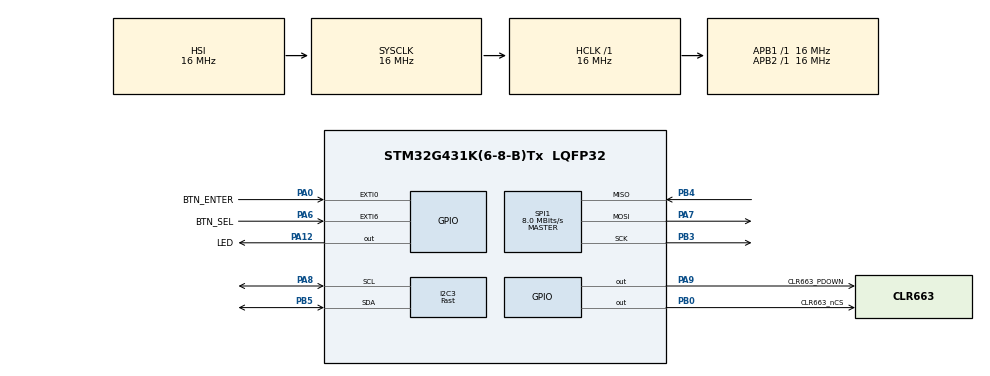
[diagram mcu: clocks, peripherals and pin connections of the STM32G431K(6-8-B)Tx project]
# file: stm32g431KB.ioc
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I2C3.I2C_Speed_Mode=I2C_Fast
I2C3.Timing=0x0010061A
Mcu.Family=STM32G4
Mcu.Name=STM32G431K(6-8-B)Tx
Mcu.Package=LQFP32
NVIC.EXTI0_IRQn=true\:5\:0\:true\:false\:true\:true\:true\:true
NVIC.EXTI9_5_IRQn=true\:5\:0\:true\:false\:true\:true\:true\:true
NVIC.PriorityGroup=NVIC_PRIORITYGROUP_4
NVIC.TIM1_BRK_TIM15_IRQn=true\:15\:0\:false\:false\:true\:false\:true\:true
NVIC.TimeBase=TIM1_BRK_TIM15_IRQn
NVIC.TimeBaseIP=TIM15
PA0.GPIO_Label=BTN_ENTER
PA0.GPIO_ModeDefaultEXTI=GPIO_MODE_IT_FALLING
PA0.GPIO_PuPd=GPIO_PULLUP
PA0.Signal=GPXTI0
PA12.GPIO_Label=LED
PA12.Signal=GPIO_Output
PA13.Mode=Serial_Wire
PA13.Signal=SYS_JTMS-SWDIO
PA14.Mode=Serial_Wire
PA14.Signal=SYS_JTCK-SWCLK
PA6.GPIO_Label=BTN_SEL
PA6.GPIO_ModeDefaultEXTI=GPIO_MODE_IT_FALLING
PA6.GPIO_PuPd=GPIO_PULLUP
PA6.Signal=GPXTI6
PA7.Mode=Full_Duplex_Master
PA7.Signal=SPI1_MOSI
PA8.Mode=I2C
PA8.Signal=I2C3_SCL
PA9.GPIO_Label=CLR663_PDOWN
PA9.PinState=GPIO_PIN_SET
PA9.Signal=GPIO_Output
PB0.GPIO_Label=CLR663_nCS
PB0.GPIO_Speed=GPIO_SPEED_FREQ_VERY_HIGH
PB0.PinState=GPIO_PIN_SET
PB0.Signal=GPIO_Output
PB3.Mode=Full_Duplex_Master
PB3.Signal=SPI1_SCK
PB4.Mode=Full_Duplex_Master
PB4.Signal=SPI1_MISO
PB5.Mode=I2C
PB5.Signal=I2C3_SDA
ProjectManager.HeapSize=0x200
ProjectManager.StackSize=0x400
ProjectManager.TargetToolchain=STM32CubeIDE
RCC.AHBFreq_Value=16000000
RCC.APB1Freq_Value=16000000
RCC.APB1TimFreq_Value=16000000
RCC.APB2Freq_Value=16000000
RCC.APB2TimFreq_Value=16000000
RCC.CortexFreq_Value=16000000
RCC.EXTERNAL_CLOCK_VALUE=12288000
RCC.HCLKFreq_Value=16000000
RCC.HSE_VALUE=8000000
RCC.HSI48_VALUE=48000000
RCC.HSI_VALUE=16000000
RCC.LSE_VALUE=32768
RCC.SYSCLKFreq_VALUE=16000000
RCC.USBFreq_Value=64000000
RCC.VCOOutputFreq_Value=128000000
SPI1.CalculateBaudRate=8.0 MBits/s
SPI1.DataSize=SPI_DATASIZE_8BIT
SPI1.Direction=SPI_DIRECTION_2LINES
SPI1.Mode=SPI_MODE_MASTER
SPI1.VirtualType=VM_MASTER
VP_SYS_VS_DBSignals.Mode=DisableDeadBatterySignals
VP_SYS_VS_tim15.Mode=TIM15
board=custom

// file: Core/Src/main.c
/* USER CODE BEGIN Header */
/**
  ******************************************************************************
  * @file           : main.c
  * @brief          : Main program body
  ******************************************************************************
  * @attention
  *
  * Copyright (c) 2026 STMicroelectronics.
  * All rights reserved.
  *
  * This software is licensed under terms that can be found in the LICENSE file
  * in the root directory of this software component.
  * If no LICENSE file comes with this software, it is provided AS-IS.
  *
  ******************************************************************************
  */
/* USER CODE END Header */
#include "main.h"
#include "i2c.h"
#include "spi.h"
#include "gpio.h"
#include "app.h"

void SystemClock_Config(void);

int main(void)
{

  /* MCU Configuration--------------------------------------------------------*/

  /* Reset of all peripherals, Initializes the Flash interface and the Systick. */
  HAL_Init();

  /* Configure the system clock */
  SystemClock_Config();

  /* Initialize all configured peripherals */
  MX_GPIO_Init();
  MX_I2C3_Init();
  MX_SPI1_Init();
  /* USER CODE BEGIN 2 */
  app_start();
  /* USER CODE END 2 */

  /* Infinite loop */
  /* USER CODE BEGIN WHILE */
  vTaskStartScheduler();
  while (1)
  {
    /* USER CODE END WHILE */

  }
}

void SystemClock_Config(void)
{
  RCC_OscInitTypeDef RCC_OscInitStruct = {0};
  RCC_ClkInitTypeDef RCC_ClkInitStruct = {0};

  /** Configure the main internal regulator output voltage
  */
  HAL_PWREx_ControlVoltageScaling(PWR_REGULATOR_VOLTAGE_SCALE1);

  /** Initializes the RCC Oscillators according to the specified parameters
  * in the RCC_OscInitTypeDef structure.
  */
  RCC_OscInitStruct.OscillatorType = RCC_OSCILLATORTYPE_HSI;
  RCC_OscInitStruct.HSIState = RCC_HSI_ON;
  RCC_OscInitStruct.HSICalibrationValue = RCC_HSICALIBRATION_DEFAULT;
  RCC_OscInitStruct.PLL.PLLState = RCC_PLL_NONE;
  if (HAL_RCC_OscConfig(&RCC_OscInitStruct) != HAL_OK)
  {
    Error_Handler();
  }

  /** Initializes the CPU, AHB and APB buses clocks
  */
  RCC_ClkInitStruct.ClockType = RCC_CLOCKTYPE_HCLK|RCC_CLOCKTYPE_SYSCLK
                              |RCC_CLOCKTYPE_PCLK1|RCC_CLOCKTYPE_PCLK2;
  RCC_ClkInitStruct.SYSCLKSource = RCC_SYSCLKSOURCE_HSI;
  RCC_ClkInitStruct.AHBCLKDivider = RCC_SYSCLK_DIV1;
  RCC_ClkInitStruct.APB1CLKDivider = RCC_HCLK_DIV1;
  RCC_ClkInitStruct.APB2CLKDivider = RCC_HCLK_DIV1;

  if (HAL_RCC_ClockConfig(&RCC_ClkInitStruct, FLASH_LATENCY_0) != HAL_OK)
  {
    Error_Handler();
  }
}

void HAL_TIM_PeriodElapsedCallback(TIM_HandleTypeDef *htim)
{
  if (htim->Instance == TIM15) {
    HAL_IncTick();
  }
}

void Error_Handler(void)
{
  __disable_irq();
  while (1)
  {
  }
}
